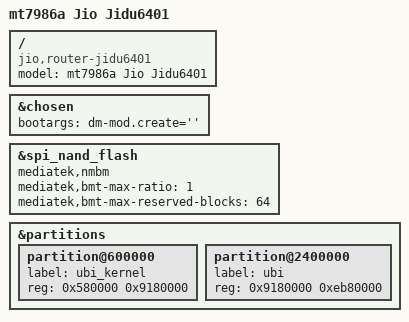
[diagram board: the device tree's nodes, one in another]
// SPDX-License-Identifier: (GPL-2.0 OR MIT)

/dts-v1/;
#include "mt7986a-jio-common.dtsi"

/ {
	model = "mt7986a Jio Jidu6401";
	compatible = "jio,router-jidu6401", "mediatek,mt7986a";
};

&chosen {
	//rootdisk = <&ubi_rootdisk>;
	//bootargs-append = " root=/dev/fit0 rootwait";
	//bootargs = "console=ttyS0,115200n1 loglevel=8 earlycon=uart8250,mmio32,0x11002000 root=/dev/fit0 rootwait dm-mod.create=''";
	bootargs = "dm-mod.create=''";
};

&spi_nand_flash {
	mediatek,nmbm;
	mediatek,bmt-max-ratio = <1>;
	mediatek,bmt-max-reserved-blocks = <64>;
};

&partitions {
	// partition@580000 {
	// 	label = "crash";
	// 	reg = <0x580000 0x40000>;
	// 	read-only;
	// };

	// partition@5c0000 {
	// 	label = "crash_log";
	// 	reg = <0x5c0000 0x40000>;
	// 	read-only;
	// };

	partition@600000 {
		label = "ubi_kernel";
		reg = <0x580000 0x9180000>;
	};

	partition@2400000 {
		label = "ubi";
		reg = <0x9180000 0xeb80000>;
	};
};

//mtd4	0x000000580000	0x000009180000	ubi
//              600000  0x     1e00000
//mtd5	0x000009180000	0x00000eb80000	ubi2
//             2400000         5000000  
